# LPC178x_7x register map
File version: 0.9
CPU: CM3 r0p0, little endian, no MPU, no FPU, 3 interrupt priority bits
Registers are 32-bit, read-write, reset 0x0 unless marked. A register's access mark holds for its fields unless they carry their own. Offsets are from the block's base; [hi:lo] are bit positions; {n}, {i} and the like mark numbered series.

## SDMMC — SD card interface
Base 0x400C0000
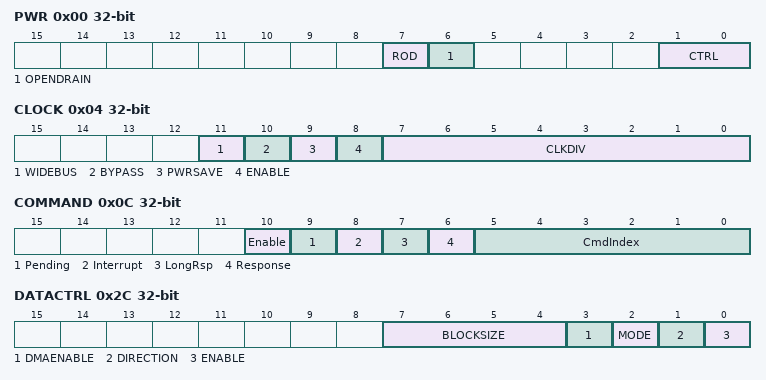
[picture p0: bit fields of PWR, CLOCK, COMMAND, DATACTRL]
0x00 PWR — Power control register.
  [7] ROD — Rod control.
  [6] OPENDRAIN — SD_CMD output control.
  [1:0] CTRL — Power control
    0=POWER_OFF; 2=POWER_UP; 3=POWER_ON
0x04 CLOCK — Clock control register.
  [11] WIDEBUS — Enable wide bus mode.
    0=STANDARD_BUS_MODE_O (Standard bus mode (only SD_DAT[0] used).); 1=WIDE_BUS_MODE_SD_DA (Wide bus mode (SD_DAT[3:0] used))
  [10] BYPASS — Enable bypass of clock divide logic:
    0=DISABLE_BYPASS_; 1=ENABLE_BYPASS_MCLK_ (Enable bypass. MCLK driven to card bus output (SD_CLK).)
  [9] PWRSAVE — Disable SD_CLK output when bus is idle:
    0=ALWAYS_ENABLED_; 1=CLOCK_ENABLED_WHEN_B (Clock enabled when bus is active.)
  [8] ENABLE — Enable SD card bus clock:
    0=CLOCK_DISABLED_; 1=CLOCK_ENABLED_
  [7:0] CLKDIV — Bus clock period: SD_CLK frequency = MCLK / [2x(ClkDiv+1)].
0x08 ARGUMENT
  [31:0] CmdArg — Command argument
0x0C COMMAND
  [10] Enable — If set, CPSM is enabled.
  [9] Pending — If set, CPSM waits for CmdPend before it starts sending a command.
  [8] Interrupt — If set, CPSM disables command timer and waits for interrupt request.
  [7] LongRsp — If set, CPSM receives a 136 bit long response.
  [6] Response — If set, CPSM waits for a response.
  [5:0] CmdIndex — Command index.
0x10 RESPCMD ro — Response command register.
  [5:0] RESPCMD — Response command index
{0x14+4i} RESPONSE{i} (i=0..3) ro
  [31:0] STATUS — Card status
0x24 DATATIMER
  [31:0] DATATIME — Data timeout period.
0x28 DATALENGTH
  [15:0] DATALENGTH — Data length value
0x2C DATACTRL — Data control register.
  [7:4] BLOCKSIZE — Data block length
  [3] DMAENABLE — Enable DMA
    0=DMA_DISABLED_; 1=DMA_ENABLED_
  [2] MODE — Data transfer mode
    0=BLOCK_DATA_TRANSFER_; 1=STREAM_DATA_TRANSFER
  [1] DIRECTION — Data transfer direction
    0=FROM_CONTROLLER_TO_C (From controller to card.); 1=FROM_CARD_TO_CONTROL (From card to controller.)
  [0] ENABLE — Data transfer enable.
0x30 DATACNT ro — Data counter.
  [15:0] DATACOUNT — Remaining data
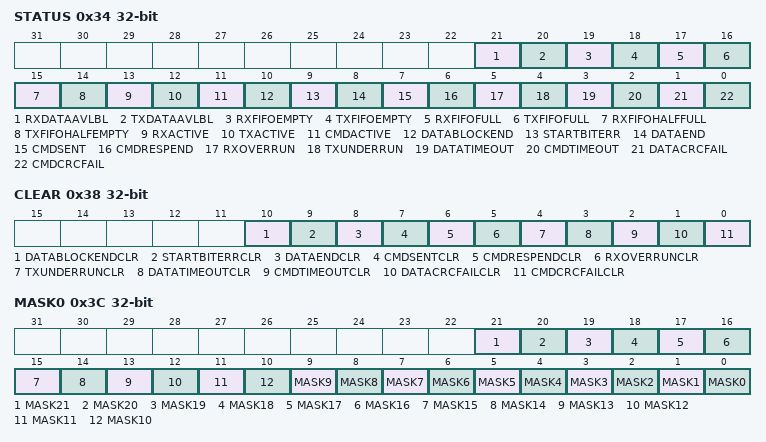
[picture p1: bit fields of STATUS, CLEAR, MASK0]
0x34 STATUS ro
  [21] RXDATAAVLBL — Data available in receive FIFO.
  [20] TXDATAAVLBL — Data available in transmit FIFO.
  [19] RXFIFOEMPTY — Receive FIFO empty.
  [18] TXFIFOEMPTY — Transmit FIFO empty.
  [17] RXFIFOFULL — Receive FIFO full.
  [16] TXFIFOFULL — Transmit FIFO full.
  [15] RXFIFOHALFFULL — Receive FIFO half full.
  [14] TXFIFOHALFEMPTY — Transmit FIFO half empty.
  [13] RXACTIVE — Data receive in progress.
  [12] TXACTIVE — Data transmit in progress.
  [11] CMDACTIVE — Command transfer in progress.
  [10] DATABLOCKEND — Data block sent/received (CRC check passed).
  [9] STARTBITERR — Start bit not detected on all data signals in wide bus mode.
  [8] DATAEND — Data end (data counter is zero).
  [7] CMDSENT — Command sent (no response required).
  [6] CMDRESPEND — Command response received (CRC check passed).
  [5] RXOVERRUN — Receive FIFO overrun error.
  [4] TXUNDERRUN — Transmit FIFO underrun error.
  [3] DATATIMEOUT
  [2] CMDTIMEOUT — Command response timeout.
  [1] DATACRCFAIL — Data block sent/received (CRC check failed).
  [0] CMDCRCFAIL — Command response received (CRC check failed).
0x38 CLEAR wo reset not defined
  [10] DATABLOCKENDCLR — Clears DataBlockEnd flag.
  [9] STARTBITERRCLR — Clears StartBitErr flag.
  [8] DATAENDCLR — Clears DataEnd flag.
  [7] CMDSENTCLR — Clears CmdSent flag.
  [6] CMDRESPENDCLR — Clears CmdRespEnd flag.
  [5] RXOVERRUNCLR — Clears RxOverrun flag.
  [4] TXUNDERRUNCLR — Clears TxUnderrun flag.
  [3] DATATIMEOUTCLR — Clears DataTimeOut flag.
  [2] CMDTIMEOUTCLR — Clears CmdTimeOut flag.
  [1] DATACRCFAILCLR — Clears DataCrcFail flag.
  [0] CMDCRCFAILCLR — Clears CmdCrcFail flag.
0x3C MASK0 — Interrupt 0 mask register.
  [21] MASK21 — Mask RxDataAvlbl flag.
  [20] MASK20 — Mask TxDataAvlbl flag.
  [19] MASK19 — Mask RxFifoEmpty flag.
  [18] MASK18 — Mask TxFifoEmpty flag.
  [17] MASK17 — Mask RxFifoFull flag.
  [16] MASK16 — Mask TxFifoFull flag.
  [15] MASK15 — Mask RxFifoHalfFull flag.
  [14] MASK14 — Mask TxFifoHalfEmpty flag.
  [13] MASK13 — Mask RxActive flag.
  [12] MASK12 — Mask TxActive flag.
  [11] MASK11 — Mask CmdActive flag.
  [10] MASK10 — Mask DataBlockEnd flag.
  [9] MASK9 — Mask StartBitErr flag.
  [8] MASK8 — Mask DataEnd flag.
  [7] MASK7 — Mask CmdSent flag.
  [6] MASK6 — Mask CmdRespEnd flag.
  [5] MASK5 — Mask RxOverrun flag.
  [4] MASK4 — Mask TxUnderrun flag.
  [3] MASK3 — Mask DataTimeOut flag.
  [2] MASK2 — Mask CmdTimeOut flag.
  [1] MASK1 — Mask DataCrcFail flag.
  [0] MASK0 — Mask CmdCrcFail flag.
0x48 FIFOCNT ro — FIFO Counter.
  [14:0] DATACOUNT — Remaining data
{0x80+4i} FIFO{i} (i=0..15) — Data FIFO Register.
  [31:0] DATA — FIFO data.
